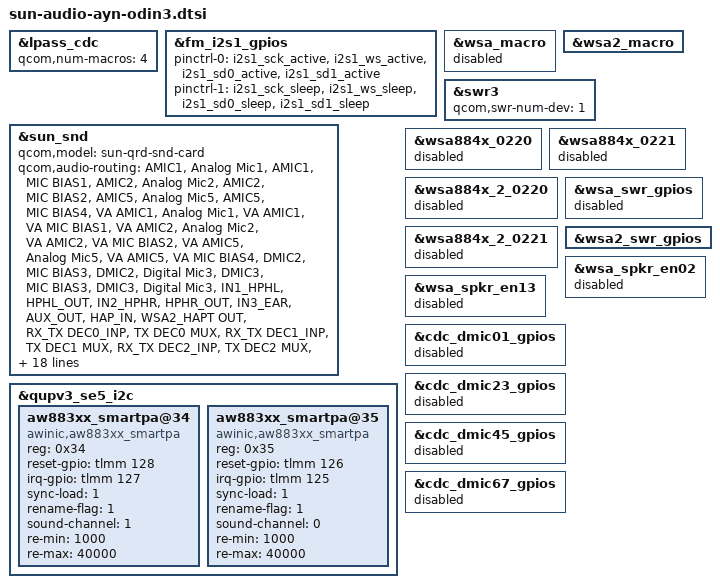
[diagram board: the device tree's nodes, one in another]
#include "../../qcom/audio/sun-audio-overlay.dtsi"

&lpass_cdc {
	qcom,num-macros = <4>;
};

&fm_i2s1_gpios {
	status = "ok";

	pinctrl-0 = <&i2s1_sck_active &i2s1_ws_active
			&i2s1_sd0_active &i2s1_sd1_active>;
	pinctrl-1 = <&i2s1_sck_sleep &i2s1_ws_sleep
			&i2s1_sd0_sleep &i2s1_sd1_sleep>;
};

&sun_snd {
	qcom,model = "sun-qrd-snd-card";

	qcom,audio-routing = 
		"AMIC1", "Analog Mic1",
		"AMIC1", "MIC BIAS1",
		"AMIC2", "Analog Mic2",
		"AMIC2", "MIC BIAS2",
		"AMIC5", "Analog Mic5",
		"AMIC5", "MIC BIAS4",
		"VA AMIC1", "Analog Mic1",
		"VA AMIC1", "VA MIC BIAS1",
		"VA AMIC2", "Analog Mic2",
		"VA AMIC2", "VA MIC BIAS2",
		"VA AMIC5", "Analog Mic5",
		"VA AMIC5", "VA MIC BIAS4",
		"DMIC2", "MIC BIAS3",
		"DMIC2", "Digital Mic3",
		"DMIC3", "MIC BIAS3",
		"DMIC3", "Digital Mic3",
		"IN1_HPHL", "HPHL_OUT",
		"IN2_HPHR", "HPHR_OUT",
		"IN3_EAR", "AUX_OUT",
		"HAP_IN", "WSA2_HAPT OUT",
		"RX_TX DEC0_INP", "TX DEC0 MUX", 
		"RX_TX DEC1_INP", "TX DEC1 MUX",
		"RX_TX DEC2_INP", "TX DEC2 MUX",
		"RX_TX DEC3_INP", "TX DEC3 MUX",
		"TX SWR_INPUT", "WCD_TX_OUTPUT",
		"VA SWR_INPUT", "VA_SWR_CLK",
		"VA SWR_INPUT", "WCD_TX_OUTPUT",
		"VA_AIF1 CAP", "VA_SWR_CLK",
		"VA_AIF2 CAP", "VA_SWR_CLK",
		"VA_AIF3 CAP", "VA_SWR_CLK",
		"VA DMIC2", "VA MIC BIAS3",
		"VA DMIC3", "VA MIC BIAS3";

	/delete-property/ qcom,cdc-dmic01-gpios;
	/delete-property/ qcom,cdc-dmic23-gpios;
	/delete-property/ qcom,cdc-dmic45-gpios;

	asoc-codec  = <&stub_codec>, <&lpass_cdc>,
				<&wcd939x_codec>, <&swr_haptics>;
	asoc-codec-names = "msm-stub-codec.1", "lpass-cdc",
				"wcd939x_codec", "swr-haptics";
	qcom,wsa-max-devs = <0>;
	qcom,sec-mi2s-gpios = <&fm_i2s1_gpios>;
	qcom,msm-mbhc-usbc-audio-supported = <1>;
	qcom,msm-mbhc-hphl-swh = <0>;
	qcom,msm-mbhc-gnd-swh = <0>;
	qcom,wcn-bt-ext = <1>;
	qcom,wcd-disable-legacy-surge;
	wcd939x-i2c-handle = <&wcd_usbss>;
};

&qupv3_se5_i2c {
	status = "ok";

	aw883xx_smartpa@34 {
		compatible = "awinic,aw883xx_smartpa";
		reg = <0x34>;
		reset-gpio = <&tlmm 128 0>;
		irq-gpio = <&tlmm 127 0>;
		sync-load = <1>;
		rename-flag = <1>;
		sound-channel = <1>;
		re-min = <1000>;
		re-max = <40000>;
		status = "okay";
	};

	aw883xx_smartpa@35 {
		compatible = "awinic,aw883xx_smartpa";
		reg = <0x35>;
		reset-gpio = <&tlmm 126 0>;
		irq-gpio = <&tlmm 125 0>;
		sync-load = <1>;
		rename-flag = <1>;
		sound-channel = <0>;
		re-min = <1000>;
		re-max = <40000>;
		status = "okay";
	};
};

&wsa_macro {
	status = "disabled";
};

&wsa2_macro {
	status = "ok";
};

&swr3 {
	qcom,swr-num-dev = <1>;
};

&wsa884x_0220 {
	status = "disabled";
};

&wsa884x_0221 {
	status = "disabled";
};

&wsa884x_2_0220 {
	status = "disabled";
};

&wsa884x_2_0221 {
	status = "disabled";
};

&wsa_swr_gpios {
	status = "disabled";
};

&wsa2_swr_gpios {
	status = "ok";
};

&wsa_spkr_en02 {
	status = "disabled";
};

&wsa_spkr_en13 {
	status = "disabled";
};

&cdc_dmic01_gpios {
	status = "disabled";
};

&cdc_dmic23_gpios {
	status = "disabled";
};

&cdc_dmic45_gpios {
	status = "disabled";
};

&cdc_dmic67_gpios {
	status = "disabled";
};
